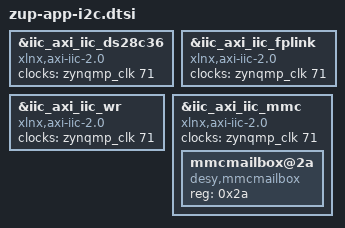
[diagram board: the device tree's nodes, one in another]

// clocks:
//   pl_clk0 -> "zynqmp_clk 71"
//   pl_clk1 -> "zynqmp_clk 72"
//   pl_clk2 -> "zynqmp_clk 73"
//   pl_clk3 -> "zynqmp_clk 74"


&iic_axi_iic_ds28c36 {
  compatible = "xlnx,axi-iic-2.0", "xlnx,xps-iic-2.00.a";
  clock-names = "s_axi_aclk";
  clocks = <&zynqmp_clk 71>;
};

&iic_axi_iic_fplink {
  compatible = "xlnx,axi-iic-2.0", "xlnx,xps-iic-2.00.a";
  clock-names = "s_axi_aclk";
  clocks = <&zynqmp_clk 71>;
};

&iic_axi_iic_wr {
  compatible = "xlnx,axi-iic-2.0", "xlnx,xps-iic-2.00.a";
  clock-names = "s_axi_aclk";
  clocks = <&zynqmp_clk 71>;
};

// TODO: Both the iic_mmc bus and the mmcmailbox device belong to the system-dt, not the app-dt
&iic_axi_iic_mmc {
  compatible = "xlnx,axi-iic-2.0", "xlnx,xps-iic-2.00.a";
  clock-names = "s_axi_aclk";
  clocks = <&zynqmp_clk 71>;

  mmcmailbox@2a {
      compatible = "desy,mmcmailbox";
      reg = <0x2a>;
  };
};
